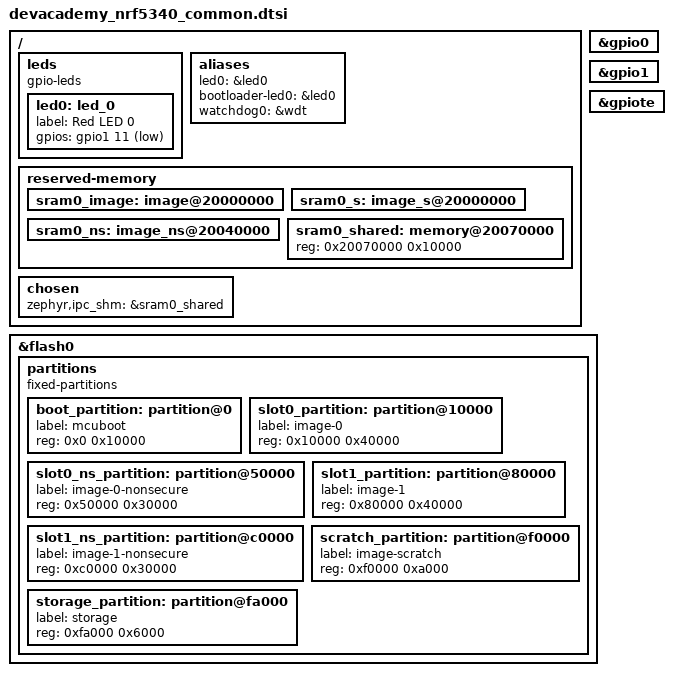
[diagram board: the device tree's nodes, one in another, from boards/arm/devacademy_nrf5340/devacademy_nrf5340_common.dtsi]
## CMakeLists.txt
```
# SPDX-License-Identifier: Apache-2.0

cmake_minimum_required(VERSION 3.20.0)
find_package(Zephyr REQUIRED HINTS $ENV{ZEPHYR_BASE})
project(blinky_devaca)

target_sources(app PRIVATE src/main.c)
```

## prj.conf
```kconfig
CONFIG_GPIO=y
CONFIG_BOOTLOADER_MCUBOOT=y

# USB
CONFIG_USB_DEVICE_STACK=y
CONFIG_UART_LINE_CTRL=y
CONFIG_USB_DEVICE_INITIALIZE_AT_BOOT=n
```

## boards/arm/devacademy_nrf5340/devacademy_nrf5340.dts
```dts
// Copyright (c) 2024 Nordic Semiconductor ASA
// SPDX-License-Identifier: Apache-2.0

/dts-v1/;
#include <nordic/nrf5340_cpuapp_qkaa.dtsi>
#include "devacademy_nrf5340-pinctrl.dtsi"

/ {
	model = "DevAcademy nRF5340";
	compatible = "hirokuma,devacademy-nrf5340";

	chosen {
		zephyr,sram = &sram0;
		zephyr,flash = &flash0;
		zephyr,code-partition = &slot0_partition;
	};

	leds {
		compatible = "gpio-leds";
		led0: led_0 {
			label = "Red LED 0";
			gpios = <&gpio1 11 GPIO_ACTIVE_LOW>;
		};
	};

	aliases {
		led0 = &led0;
		bootloader-led0 = &led0;
		watchdog0 = &wdt;
	};
};

&flash0 {
	partitions {
		compatible = "fixed-partitions";
		#address-cells = <1>;
		#size-cells = <1>;

		boot_partition: partition@0 {
			label = "mcuboot";
			reg = <0x0 0x10000>;
		};
		slot0_partition: partition@10000 {
			label = "image-0";
			reg = <0x10000 0x40000>;
		};
		slot0_ns_partition: partition@50000 {
			label = "image-0-nonsecure";
			reg = <0x50000 0x30000>;
		};
		slot1_partition: partition@80000 {
			label = "image-1";
			reg = <0x80000 0x40000>;
		};
		slot1_ns_partition: partition@c0000 {
			label = "image-1-nonsecure";
			reg = <0xc0000 0x30000>;
		};
		scratch_partition: partition@f0000 {
			label = "image-scratch";
			reg = <0xf0000 0xa000>;
		};
		storage_partition: partition@fa000 {
			label = "storage";
			reg = <0xfa000 0x6000>;
		};
	};
};



/* Default shared SRAM planning when building for nRF5340.
* This file is included by both nRF5340 CPUAPP (Application MCU)
* and nRF5340 CPUNET (Network MCU).
* - 64 kB SRAM allocated as Shared memory (sram0_shared)
* - Region defined after the image SRAM of Application MCU
*/

/ {
    chosen {
        /* shared memory reserved for the inter-processor communication */
        zephyr,ipc_shm = &sram0_shared;
    };

    reserved-memory {
        #address-cells = <1>;
        #size-cells = <1>;
        ranges;

        sram0_shared: memory@20070000 {
            /* SRAM allocated to shared memory */
            reg = <0x20070000 0x10000>;
        };
    };
};

&gpio0 {
	status = "okay";
};

&gpio1 {
	status = "okay";
};

&gpiote {
	status = "okay";
};
```

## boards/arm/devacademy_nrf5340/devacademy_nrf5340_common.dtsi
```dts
/ {
	leds {
		compatible = "gpio-leds";
		led0: led_0 {
			label = "Red LED 0";
			gpios = <&gpio1 11 GPIO_ACTIVE_LOW>;
		};
	};

	aliases {
		led0 = &led0;
		bootloader-led0 = &led0;
		watchdog0 = &wdt;
	};
};

&gpio0 {
	status = "okay";
};

&gpio1 {
	status = "okay";
};

&gpiote {
	status = "okay";
};

&flash0 {
	partitions {
		compatible = "fixed-partitions";
		#address-cells = <1>;
		#size-cells = <1>;

		boot_partition: partition@0 {
			label = "mcuboot";
			reg = <0x0 0x10000>;
		};
		slot0_partition: partition@10000 {
			label = "image-0";
			reg = <0x10000 0x40000>;
		};
		slot0_ns_partition: partition@50000 {
			label = "image-0-nonsecure";
			reg = <0x50000 0x30000>;
		};
		slot1_partition: partition@80000 {
			label = "image-1";
			reg = <0x80000 0x40000>;
		};
		slot1_ns_partition: partition@c0000 {
			label = "image-1-nonsecure";
			reg = <0xc0000 0x30000>;
		};
		scratch_partition: partition@f0000 {
			label = "image-scratch";
			reg = <0xf0000 0xa000>;
		};
		storage_partition: partition@fa000 {
			label = "storage";
			reg = <0xfa000 0x6000>;
		};
	};
};

/* Default shared SRAM planning when building for nRF5340.
* This file is included by both nRF5340 CPUAPP (Application MCU)
* and nRF5340 CPUNET (Network MCU).
* - 64 kB SRAM allocated as Shared memory (sram0_shared)
* - Region defined after the image SRAM of Application MCU
*/

/ {
	reserved-memory {
		#address-cells = <1>;
		#size-cells = <1>;
		ranges;

		sram0_image: image@20000000 {
			/* Zephyr image(s) memory */
		};

		sram0_s: image_s@20000000 {
			/* Secure image memory */
		};

		sram0_ns: image_ns@20040000 {
			/* Non-Secure image memory */
		};
	};
};

/ {
	chosen {
		/* shared memory reserved for the inter-processor communication */
		zephyr,ipc_shm = &sram0_shared;
	};

	reserved-memory {
		#address-cells = <1>;
		#size-cells = <1>;
		ranges;

		sram0_shared: memory@20070000 {
			/* SRAM allocated to shared memory */
			reg = <0x20070000 0x10000>;
		};
	};
};

#include "devacademy_nrf5340_partition_conf.dtsi"
```

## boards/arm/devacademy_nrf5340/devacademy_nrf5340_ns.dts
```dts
// Copyright (c) 2024 Nordic Semiconductor ASA
// SPDX-License-Identifier: Apache-2.0

/dts-v1/;
#include <nordic/nrf5340_cpuappns_qkaa.dtsi>
#include "devacademy_nrf5340_common.dtsi"
#include "devacademy_nrf5340-pinctrl.dtsi"

/ {
	model = "DevAcademy nRF5340";
	compatible = "hirokuma,devacademy-nrf5340";

	chosen {
		zephyr,sram = &sram0_ns;
		zephyr,flash = &flash0;
		zephyr,code-partition = &slot0_ns_partition;
	};
};
```

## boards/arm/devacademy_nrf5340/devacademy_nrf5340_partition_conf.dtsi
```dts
/*
 * Copyright (c) 2021 Nordic Semiconductor ASA
 *
 * SPDX-License-Identifier: Apache-2.0
 */

/*
 * Default Flash planning for thingy53_nrf5340.
 *
 * Zephyr build for nRF5340 with ARM TrustZone-M support,
 * implies building Secure and Non-Secure Zephyr images.
 *
 * Secure image will be placed, by default, in flash0
 * (or in slot0, if MCUboot is present).
 * Secure image will use sram0 for system memory.
 *
 * Non-Secure image will be placed in slot0_ns, and use
 * sram0_ns for system memory.
 *
 * Note that the Secure image only requires knowledge of
 * the beginning of the Non-Secure image (not its size).
 */

&slot0_partition {
	reg = <0x00010000 0x40000>;
};

&slot0_ns_partition {
	reg = <0x00050000 0x30000>;
};

&slot1_partition {
	reg = <0x00080000 0x40000>;
};

&slot1_ns_partition {
	reg = <0x000c0000 0x30000>;
};

/* Default SRAM planning when building for nRF5340 with
 * ARM TrustZone-M support
 * - Lowest 256 kB SRAM allocated to Secure image (sram0_s)
 * - Middle 192 kB allocated to Non-Secure image (sram0_ns)
 * - Upper 64 kB SRAM allocated as Shared memory (sram0_shared)
 *   (see nrf5340_shared_sram_planning_conf.dts)
 */
&sram0_image {
	reg = <0x20000000 DT_SIZE_K(448)>;
};

&sram0_s {
	reg = <0x20000000 0x40000>;
};

&sram0_ns {
	reg = <0x20040000 0x30000>;
};
```

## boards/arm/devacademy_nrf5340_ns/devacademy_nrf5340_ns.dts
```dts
// Copyright (c) 2024 Nordic Semiconductor ASA
// SPDX-License-Identifier: Apache-2.0

/dts-v1/;
#include <nordic/nrf5340_cpuappns_qkaa.dtsi>
#include "devacademy_nrf5340-pinctrl.dtsi"

/ {
	model = "DevAcademy NS nRF5340";
	compatible = "hirokuma,devacademy-nrf5340-ns";

	chosen {
		zephyr,sram = &sram0;
		zephyr,flash = &flash0;
		zephyr,code-partition = &slot0_ns_partition;
	};

	leds {
		compatible = "gpio-leds";
		led0: led_0 {
			label = "Red LED 0";
			gpios = <&gpio1 11 GPIO_ACTIVE_LOW>;
		};
	};

	aliases {
		led0 = &led0;
		bootloader-led0 = &led0;
		watchdog0 = &wdt;
	};
};

&flash0 {
	partitions {
		compatible = "fixed-partitions";
		#address-cells = <1>;
		#size-cells = <1>;

		boot_partition: partition@0 {
			label = "mcuboot";
			reg = <0x0 0x10000>;
		};
		slot0_partition: partition@10000 {
			label = "image-0";
			reg = <0x10000 0x40000>;
		};
		slot0_ns_partition: partition@50000 {
			label = "image-0-nonsecure";
			reg = <0x50000 0x30000>;
		};
		slot1_partition: partition@80000 {
			label = "image-1";
			reg = <0x80000 0x40000>;
		};
		slot1_ns_partition: partition@c0000 {
			label = "image-1-nonsecure";
			reg = <0xc0000 0x30000>;
		};
		scratch_partition: partition@f0000 {
			label = "image-scratch";
			reg = <0xf0000 0xa000>;
		};
		storage_partition: partition@fa000 {
			label = "storage";
			reg = <0xfa000 0x6000>;
		};
	};
};



/* Default shared SRAM planning when building for nRF5340.
* This file is included by both nRF5340 CPUAPP (Application MCU)
* and nRF5340 CPUNET (Network MCU).
* - 64 kB SRAM allocated as Shared memory (sram0_shared)
* - Region defined after the image SRAM of Application MCU
*/

/ {
    chosen {
        /* shared memory reserved for the inter-processor communication */
        zephyr,ipc_shm = &sram0_shared;
    };

    reserved-memory {
        #address-cells = <1>;
        #size-cells = <1>;
        ranges;

        sram0_shared: memory@20070000 {
            /* SRAM allocated to shared memory */
            reg = <0x20070000 0x10000>;
        };
    };
};

&gpio0 {
	status = "okay";
};

&gpio1 {
	status = "okay";
};

&gpiote {
	status = "okay";
};
```

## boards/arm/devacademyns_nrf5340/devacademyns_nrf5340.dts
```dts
// Copyright (c) 2024 Nordic Semiconductor ASA
// SPDX-License-Identifier: Apache-2.0

/dts-v1/;
#include <nordic/nrf5340_cpuappns_qkaa.dtsi>
#include "devacademyns_nrf5340-pinctrl.dtsi"

/ {
	model = "DevAcademyNS nRF5340";
	compatible = "hirokuma,devacademyns-nrf5340";

	chosen {
		zephyr,sram = &sram0;
		zephyr,flash = &flash0;
		zephyr,code-partition = &slot0_ns_partition;
	};

	leds {
		compatible = "gpio-leds";
		led0: led_0 {
			label = "Red LED 0";
			gpios = <&gpio1 11 GPIO_ACTIVE_LOW>;
		};
	};

	aliases {
		led0 = &led0;
		bootloader-led0 = &led0;
		watchdog0 = &wdt;
	};
};

&flash0 {
	partitions {
		compatible = "fixed-partitions";
		#address-cells = <1>;
		#size-cells = <1>;

		boot_partition: partition@0 {
			label = "mcuboot";
			reg = <0x0 0x10000>;
		};
		slot0_partition: partition@10000 {
			label = "image-0";
			reg = <0x10000 0x40000>;
		};
		slot0_ns_partition: partition@50000 {
			label = "image-0-nonsecure";
			reg = <0x50000 0x30000>;
		};
		slot1_partition: partition@80000 {
			label = "image-1";
			reg = <0x80000 0x40000>;
		};
		slot1_ns_partition: partition@c0000 {
			label = "image-1-nonsecure";
			reg = <0xc0000 0x30000>;
		};
		scratch_partition: partition@f0000 {
			label = "image-scratch";
			reg = <0xf0000 0xa000>;
		};
		storage_partition: partition@fa000 {
			label = "storage";
			reg = <0xfa000 0x6000>;
		};
	};
};



/* Default shared SRAM planning when building for nRF5340.
* This file is included by both nRF5340 CPUAPP (Application MCU)
* and nRF5340 CPUNET (Network MCU).
* - 64 kB SRAM allocated as Shared memory (sram0_shared)
* - Region defined after the image SRAM of Application MCU
*/

/ {
    chosen {
        /* shared memory reserved for the inter-processor communication */
        zephyr,ipc_shm = &sram0_shared;
    };

    reserved-memory {
        #address-cells = <1>;
        #size-cells = <1>;
        ranges;

        sram0_shared: memory@20070000 {
            /* SRAM allocated to shared memory */
            reg = <0x20070000 0x10000>;
        };
    };
};

&gpio0 {
	status = "okay";
};

&gpio1 {
	status = "okay";
};

&gpiote {
	status = "okay";
};
```

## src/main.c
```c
/*
 * Copyright (c) 2016 Intel Corporation
 *
 * SPDX-License-Identifier: Apache-2.0
 */

#include <zephyr/kernel.h>
#include <zephyr/drivers/gpio.h>

#include <zephyr/usb/usb_device.h>

/* 1000 msec = 1 sec */
#define SLEEP_TIME_MS   1000

/* The devicetree node identifier for the "led0" alias. */
#define LED0_NODE DT_ALIAS(led0)

/*
 * A build error on this line means your board is unsupported.
 * See the sample documentation for information on how to fix this.
 */
static const struct gpio_dt_spec led = GPIO_DT_SPEC_GET(LED0_NODE, gpios);

int main(void)
{
	int ret;

	if (IS_ENABLED(CONFIG_USB_DEVICE_STACK)) {
		ret = usb_enable(NULL);
		if (ret) {
			return 0;
		}
	}
	printk("Hello!\n");

	if (!gpio_is_ready_dt(&led)) {
		return 0;
	}

	ret = gpio_pin_configure_dt(&led, GPIO_OUTPUT_ACTIVE);
	if (ret < 0) {
		return 0;
	}

	int cnt = 0;
	while (1) {
		printk("toggle - %d\n", cnt);
		cnt++;
		ret = gpio_pin_toggle_dt(&led);
		if (ret < 0) {
			return 0;
		}
		k_msleep(SLEEP_TIME_MS);
	}
	return 0;
}
```
